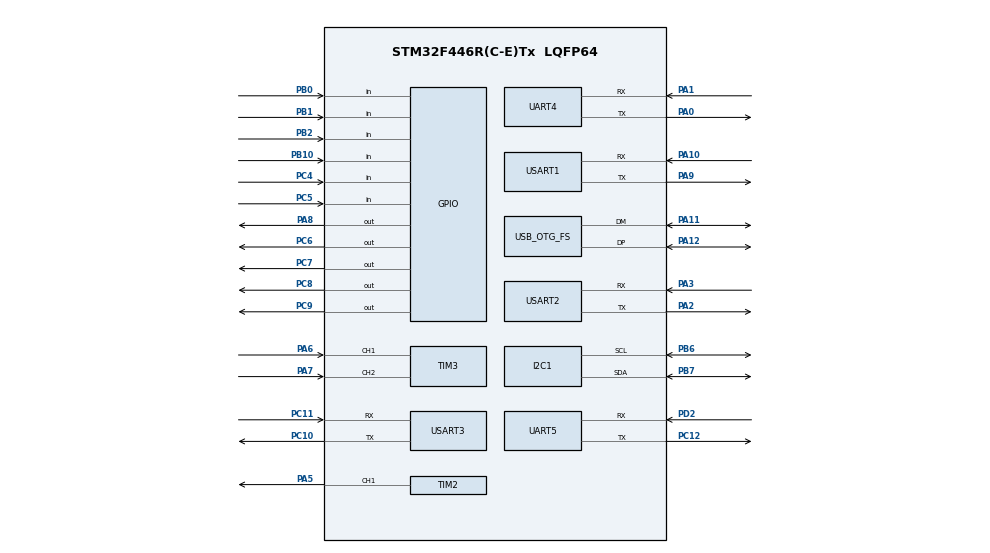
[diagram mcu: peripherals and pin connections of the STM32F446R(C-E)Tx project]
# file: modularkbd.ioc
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Mcu.Family=STM32F4
Mcu.Name=STM32F446R(C-E)Tx
Mcu.Package=LQFP64
NVIC.OTG_FS_IRQn=true\:0\:0\:false\:false\:true\:false\:true\:true
NVIC.PriorityGroup=NVIC_PRIORITYGROUP_4
PA0-WKUP.Mode=Asynchronous
PA0-WKUP.Signal=UART4_TX
PA1.Mode=Asynchronous
PA1.Signal=UART4_RX
PA10.Mode=Asynchronous
PA10.Signal=USART1_RX
PA11.Mode=Device_Only
PA11.Signal=USB_OTG_FS_DM
PA12.Mode=Device_Only
PA12.Signal=USB_OTG_FS_DP
PA13.Mode=JTAG_5_pins
PA13.Signal=SYS_JTMS-SWDIO
PA14.Mode=JTAG_5_pins
PA14.Signal=SYS_JTCK-SWCLK
PA15.Mode=JTAG_5_pins
PA15.Signal=SYS_JTDI
PA2.Mode=Asynchronous
PA2.Signal=USART2_TX
PA3.Mode=Asynchronous
PA3.Signal=USART2_RX
PA5.Signal=S_TIM2_CH1_ETR
PA6.Signal=S_TIM3_CH1
PA7.Signal=S_TIM3_CH2
PA8.Signal=GPIO_Output
PA9.Mode=Asynchronous
PA9.Signal=USART1_TX
PB0.Signal=GPIO_Input
PB1.Signal=GPIO_Input
PB10.Signal=GPIO_Input
PB2.Signal=GPIO_Input
PB3.Mode=JTAG_5_pins
PB3.Signal=SYS_JTDO-SWO
PB4.Mode=JTAG_5_pins
PB4.Signal=SYS_JTRST
PB6.Mode=I2C
PB6.Signal=I2C1_SCL
PB7.Mode=I2C
PB7.Signal=I2C1_SDA
PC10.Mode=Asynchronous
PC10.Signal=USART3_TX
PC11.Mode=Asynchronous
PC11.Signal=USART3_RX
PC12.Mode=Asynchronous
PC12.Signal=UART5_TX
PC4.Signal=GPIO_Input
PC5.Signal=GPIO_Input
PC6.Signal=GPIO_Output
PC7.Signal=GPIO_Output
PC8.Signal=GPIO_Output
PC9.Signal=GPIO_Output
PD2.Mode=Asynchronous
PD2.Signal=UART5_RX
PH0-OSC_IN.Mode=HSE-External-Oscillator
PH0-OSC_IN.Signal=RCC_OSC_IN
PH1-OSC_OUT.Mode=HSE-External-Oscillator
PH1-OSC_OUT.Signal=RCC_OSC_OUT
ProjectManager.HeapSize=0x200
ProjectManager.StackSize=0x400
ProjectManager.TargetToolchain=STM32CubeIDE
RCC.CortexFreq_Value=16000000
RCC.HSE_VALUE=8000000
RCC.PLLM=4
RCC.PLLN=72
RCC.PLLQ=3
RCC.USBFreq_Value=48000000
RCC.VCOOutputFreq_Value=144000000
SH.S_TIM2_CH1_ETR.0=TIM2_CH1,Forced Output1 CH1
SH.S_TIM3_CH1.0=TIM3_CH1,Encoder_Interface
SH.S_TIM3_CH2.0=TIM3_CH2,Encoder_Interface
TIM2.Channel-Forced\ Output1\ CH1=TIM_CHANNEL_1
UART4.VirtualMode=Asynchronous
UART5.VirtualMode=Asynchronous
USART1.VirtualMode=VM_ASYNC
USART2.VirtualMode=VM_ASYNC
USART3.VirtualMode=VM_ASYNC
USB_DEVICE.CLASS_NAME_FS=HID
USB_DEVICE.MANUFACTURER_STRING-HID_FS=Team SKBD
USB_DEVICE.PRODUCT_STRING_HID_FS=Modular Keyboard
USB_DEVICE.VirtualMode-HID_FS=Hid
USB_DEVICE.VirtualModeFS=Hid_FS
USB_OTG_FS.VirtualMode=Device_Only
VP_USB_DEVICE_VS_USB_DEVICE_HID_FS.Mode=HID_FS
board=custom

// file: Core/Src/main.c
/* USER CODE BEGIN Header */
/**
  ******************************************************************************
  * @file           : main.c
  * @brief          : Main program body
  ******************************************************************************
  * @attention
  *
  * Copyright (c) 2025 STMicroelectronics.
  * All rights reserved.
  *
  * This software is licensed under terms that can be found in the LICENSE file
  * in the root directory of this software component.
  * If no LICENSE file comes with this software, it is provided AS-IS.
  *
  ******************************************************************************
  */
/* USER CODE END Header */
#include "main.h"
#include "usb_device.h"

/* USER CODE BEGIN Includes */
#include "usbd_hid.h"
/* USER CODE END Includes */

I2C_HandleTypeDef hi2c1;

TIM_HandleTypeDef htim2;
TIM_HandleTypeDef htim3;

UART_HandleTypeDef huart4;
UART_HandleTypeDef huart5;
UART_HandleTypeDef huart1;
UART_HandleTypeDef huart2;
UART_HandleTypeDef huart3;

void SystemClock_Config(void);
static void MX_GPIO_Init(void);
static void MX_TIM2_Init(void);
static void MX_TIM3_Init(void);
static void MX_UART4_Init(void);
static void MX_UART5_Init(void);
static void MX_USART1_UART_Init(void);
static void MX_USART2_UART_Init(void);
static void MX_I2C1_Init(void);
static void MX_USART3_UART_Init(void);

int main(void)
{

  /* MCU Configuration--------------------------------------------------------*/

  /* Reset of all peripherals, Initializes the Flash interface and the Systick. */
  HAL_Init();

  /* Configure the system clock */
  SystemClock_Config();

  /* Initialize all configured peripherals */
  MX_GPIO_Init();
  MX_TIM2_Init();
  MX_TIM3_Init();
  MX_UART4_Init();
  MX_UART5_Init();
  MX_USART1_UART_Init();
  MX_USART2_UART_Init();
  MX_I2C1_Init();
  MX_USART3_UART_Init();
  MX_USB_DEVICE_Init();

  /* Infinite loop */
  while (1)
  {

  }
}

void SystemClock_Config(void)
{
  RCC_OscInitTypeDef RCC_OscInitStruct = {0};
  RCC_ClkInitTypeDef RCC_ClkInitStruct = {0};

  /** Configure the main internal regulator output voltage
  */
  __HAL_RCC_PWR_CLK_ENABLE();
  __HAL_PWR_VOLTAGESCALING_CONFIG(PWR_REGULATOR_VOLTAGE_SCALE3);

  /** Initializes the RCC Oscillators according to the specified parameters
  * in the RCC_OscInitTypeDef structure.
  */
  RCC_OscInitStruct.OscillatorType = RCC_OSCILLATORTYPE_HSI;
  RCC_OscInitStruct.HSIState = RCC_HSI_ON;
  RCC_OscInitStruct.HSICalibrationValue = RCC_HSICALIBRATION_DEFAULT;
  RCC_OscInitStruct.PLL.PLLState = RCC_PLL_ON;
  RCC_OscInitStruct.PLL.PLLSource = RCC_PLLSOURCE_HSE;
  RCC_OscInitStruct.PLL.PLLM = 4;
  RCC_OscInitStruct.PLL.PLLN = 72;
  RCC_OscInitStruct.PLL.PLLP = RCC_PLLP_DIV2;
  RCC_OscInitStruct.PLL.PLLQ = 3;
  RCC_OscInitStruct.PLL.PLLR = 2;
  if (HAL_RCC_OscConfig(&RCC_OscInitStruct) != HAL_OK)
  {
    Error_Handler();
  }

  /** Initializes the CPU, AHB and APB buses clocks
  */
  RCC_ClkInitStruct.ClockType = RCC_CLOCKTYPE_HCLK|RCC_CLOCKTYPE_SYSCLK
                              |RCC_CLOCKTYPE_PCLK1|RCC_CLOCKTYPE_PCLK2;
  RCC_ClkInitStruct.SYSCLKSource = RCC_SYSCLKSOURCE_HSI;
  RCC_ClkInitStruct.AHBCLKDivider = RCC_SYSCLK_DIV1;
  RCC_ClkInitStruct.APB1CLKDivider = RCC_HCLK_DIV1;
  RCC_ClkInitStruct.APB2CLKDivider = RCC_HCLK_DIV1;

  if (HAL_RCC_ClockConfig(&RCC_ClkInitStruct, FLASH_LATENCY_0) != HAL_OK)
  {
    Error_Handler();
  }
}

static void MX_I2C1_Init(void)
{

  hi2c1.Instance = I2C1;
  hi2c1.Init.ClockSpeed = 100000;
  hi2c1.Init.DutyCycle = I2C_DUTYCYCLE_2;
  hi2c1.Init.OwnAddress1 = 0;
  hi2c1.Init.AddressingMode = I2C_ADDRESSINGMODE_7BIT;
  hi2c1.Init.DualAddressMode = I2C_DUALADDRESS_DISABLE;
  hi2c1.Init.OwnAddress2 = 0;
  hi2c1.Init.GeneralCallMode = I2C_GENERALCALL_DISABLE;
  hi2c1.Init.NoStretchMode = I2C_NOSTRETCH_DISABLE;
  if (HAL_I2C_Init(&hi2c1) != HAL_OK)
  {
    Error_Handler();
  }

}

static void MX_TIM2_Init(void)
{

  TIM_MasterConfigTypeDef sMasterConfig = {0};
  TIM_OC_InitTypeDef sConfigOC = {0};

  htim2.Instance = TIM2;
  htim2.Init.Prescaler = 0;
  htim2.Init.CounterMode = TIM_COUNTERMODE_UP;
  htim2.Init.Period = 4294967295;
  htim2.Init.ClockDivision = TIM_CLOCKDIVISION_DIV1;
  htim2.Init.AutoReloadPreload = TIM_AUTORELOAD_PRELOAD_DISABLE;
  if (HAL_TIM_OC_Init(&htim2) != HAL_OK)
  {
    Error_Handler();
  }
  sMasterConfig.MasterOutputTrigger = TIM_TRGO_RESET;
  sMasterConfig.MasterSlaveMode = TIM_MASTERSLAVEMODE_DISABLE;
  if (HAL_TIMEx_MasterConfigSynchronization(&htim2, &sMasterConfig) != HAL_OK)
  {
    Error_Handler();
  }
  sConfigOC.OCMode = TIM_OCMODE_FORCED_ACTIVE;
  sConfigOC.Pulse = 0;
  sConfigOC.OCPolarity = TIM_OCPOLARITY_HIGH;
  sConfigOC.OCFastMode = TIM_OCFAST_DISABLE;
  if (HAL_TIM_OC_ConfigChannel(&htim2, &sConfigOC, TIM_CHANNEL_1) != HAL_OK)
  {
    Error_Handler();
  }
  HAL_TIM_MspPostInit(&htim2);

}

static void MX_TIM3_Init(void)
{

  TIM_Encoder_InitTypeDef sConfig = {0};
  TIM_MasterConfigTypeDef sMasterConfig = {0};

  htim3.Instance = TIM3;
  htim3.Init.Prescaler = 0;
  htim3.Init.CounterMode = TIM_COUNTERMODE_UP;
  htim3.Init.Period = 65535;
  htim3.Init.ClockDivision = TIM_CLOCKDIVISION_DIV1;
  htim3.Init.AutoReloadPreload = TIM_AUTORELOAD_PRELOAD_DISABLE;
  sConfig.EncoderMode = TIM_ENCODERMODE_TI1;
  sConfig.IC1Polarity = TIM_ICPOLARITY_RISING;
  sConfig.IC1Selection = TIM_ICSELECTION_DIRECTTI;
  sConfig.IC1Prescaler = TIM_ICPSC_DIV1;
  sConfig.IC1Filter = 0;
  sConfig.IC2Polarity = TIM_ICPOLARITY_RISING;
  sConfig.IC2Selection = TIM_ICSELECTION_DIRECTTI;
  sConfig.IC2Prescaler = TIM_ICPSC_DIV1;
  sConfig.IC2Filter = 0;
  if (HAL_TIM_Encoder_Init(&htim3, &sConfig) != HAL_OK)
  {
    Error_Handler();
  }
  sMasterConfig.MasterOutputTrigger = TIM_TRGO_RESET;
  sMasterConfig.MasterSlaveMode = TIM_MASTERSLAVEMODE_DISABLE;
  if (HAL_TIMEx_MasterConfigSynchronization(&htim3, &sMasterConfig) != HAL_OK)
  {
    Error_Handler();
  }

}

static void MX_UART4_Init(void)
{

  huart4.Instance = UART4;
  huart4.Init.BaudRate = 115200;
  huart4.Init.WordLength = UART_WORDLENGTH_8B;
  huart4.Init.StopBits = UART_STOPBITS_1;
  huart4.Init.Parity = UART_PARITY_NONE;
  huart4.Init.Mode = UART_MODE_TX_RX;
  huart4.Init.HwFlowCtl = UART_HWCONTROL_NONE;
  huart4.Init.OverSampling = UART_OVERSAMPLING_16;
  if (HAL_UART_Init(&huart4) != HAL_OK)
  {
    Error_Handler();
  }

}

static void MX_UART5_Init(void)
{

  huart5.Instance = UART5;
  huart5.Init.BaudRate = 115200;
  huart5.Init.WordLength = UART_WORDLENGTH_8B;
  huart5.Init.StopBits = UART_STOPBITS_1;
  huart5.Init.Parity = UART_PARITY_NONE;
  huart5.Init.Mode = UART_MODE_TX_RX;
  huart5.Init.HwFlowCtl = UART_HWCONTROL_NONE;
  huart5.Init.OverSampling = UART_OVERSAMPLING_16;
  if (HAL_UART_Init(&huart5) != HAL_OK)
  {
    Error_Handler();
  }

}

static void MX_USART1_UART_Init(void)
{

  huart1.Instance = USART1;
  huart1.Init.BaudRate = 115200;
  huart1.Init.WordLength = UART_WORDLENGTH_8B;
  huart1.Init.StopBits = UART_STOPBITS_1;
  huart1.Init.Parity = UART_PARITY_NONE;
  huart1.Init.Mode = UART_MODE_TX_RX;
  huart1.Init.HwFlowCtl = UART_HWCONTROL_NONE;
  huart1.Init.OverSampling = UART_OVERSAMPLING_16;
  if (HAL_UART_Init(&huart1) != HAL_OK)
  {
    Error_Handler();
  }

}

static void MX_USART2_UART_Init(void)
{

  huart2.Instance = USART2;
  huart2.Init.BaudRate = 115200;
  huart2.Init.WordLength = UART_WORDLENGTH_8B;
  huart2.Init.StopBits = UART_STOPBITS_1;
  huart2.Init.Parity = UART_PARITY_NONE;
  huart2.Init.Mode = UART_MODE_TX_RX;
  huart2.Init.HwFlowCtl = UART_HWCONTROL_NONE;
  huart2.Init.OverSampling = UART_OVERSAMPLING_16;
  if (HAL_UART_Init(&huart2) != HAL_OK)
  {
    Error_Handler();
  }

}

static void MX_USART3_UART_Init(void)
{

  huart3.Instance = USART3;
  huart3.Init.BaudRate = 115200;
  huart3.Init.WordLength = UART_WORDLENGTH_8B;
  huart3.Init.StopBits = UART_STOPBITS_1;
  huart3.Init.Parity = UART_PARITY_NONE;
  huart3.Init.Mode = UART_MODE_TX_RX;
  huart3.Init.HwFlowCtl = UART_HWCONTROL_NONE;
  huart3.Init.OverSampling = UART_OVERSAMPLING_16;
  if (HAL_UART_Init(&huart3) != HAL_OK)
  {
    Error_Handler();
  }

}

static void MX_GPIO_Init(void)
{
  GPIO_InitTypeDef GPIO_InitStruct = {0};

  /* GPIO Ports Clock Enable */
  __HAL_RCC_GPIOH_CLK_ENABLE();
  __HAL_RCC_GPIOA_CLK_ENABLE();
  __HAL_RCC_GPIOC_CLK_ENABLE();
  __HAL_RCC_GPIOB_CLK_ENABLE();
  __HAL_RCC_GPIOD_CLK_ENABLE();

  /*Configure GPIO pin Output Level */
  HAL_GPIO_WritePin(GPIOC, GPIO_PIN_6|GPIO_PIN_7|GPIO_PIN_8|GPIO_PIN_9, GPIO_PIN_RESET);

  /*Configure GPIO pin Output Level */
  HAL_GPIO_WritePin(GPIOA, GPIO_PIN_8, GPIO_PIN_RESET);

  /*Configure GPIO pins : PC4 PC5 */
  GPIO_InitStruct.Pin = GPIO_PIN_4|GPIO_PIN_5;
  GPIO_InitStruct.Mode = GPIO_MODE_INPUT;
  GPIO_InitStruct.Pull = GPIO_NOPULL;
  HAL_GPIO_Init(GPIOC, &GPIO_InitStruct);

  /*Configure GPIO pins : PB0 PB1 PB2 PB10 */
  GPIO_InitStruct.Pin = GPIO_PIN_0|GPIO_PIN_1|GPIO_PIN_2|GPIO_PIN_10;
  GPIO_InitStruct.Mode = GPIO_MODE_INPUT;
  GPIO_InitStruct.Pull = GPIO_NOPULL;
  HAL_GPIO_Init(GPIOB, &GPIO_InitStruct);

  /*Configure GPIO pins : PC6 PC7 PC8 PC9 */
  GPIO_InitStruct.Pin = GPIO_PIN_6|GPIO_PIN_7|GPIO_PIN_8|GPIO_PIN_9;
  GPIO_InitStruct.Mode = GPIO_MODE_OUTPUT_PP;
  GPIO_InitStruct.Pull = GPIO_NOPULL;
  GPIO_InitStruct.Speed = GPIO_SPEED_FREQ_LOW;
  HAL_GPIO_Init(GPIOC, &GPIO_InitStruct);

  /*Configure GPIO pin : PA8 */
  GPIO_InitStruct.Pin = GPIO_PIN_8;
  GPIO_InitStruct.Mode = GPIO_MODE_OUTPUT_PP;
  GPIO_InitStruct.Pull = GPIO_NOPULL;
  GPIO_InitStruct.Speed = GPIO_SPEED_FREQ_LOW;
  HAL_GPIO_Init(GPIOA, &GPIO_InitStruct);

}

void Error_Handler(void)
{
  __disable_irq();
  while (1)
  {
  }
}
